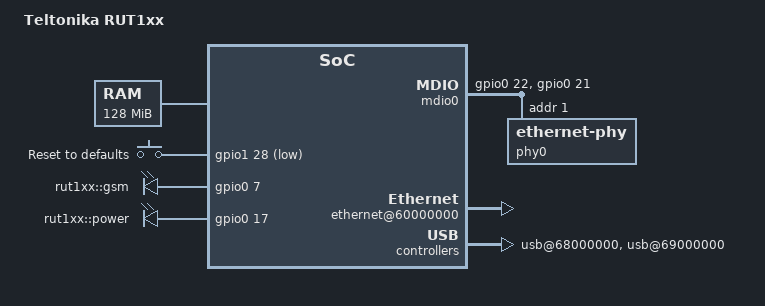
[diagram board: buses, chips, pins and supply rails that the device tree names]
/dts-v1/;
#include "gemini.dtsi"
#include <dt-bindings/input/input.h>
/ {
	model = "Teltonika RUT1xx";
	compatible = "teltonika,rut1xx", "cortina,gemini";
	#address-cells = <1>;
	#size-cells = <1>;
	memory@0 {  
		device_type = "memory";
		reg = <0x00000000 0x8000000>;
	};
	chosen {
		bootargs = "console=ttyS0,115200n8";
		stdout-path = &uart0;
	};
	gpio_keys {
		compatible = "gpio-keys";
		button-setup {
			debounce-interval = <100>;
			wakeup-source;
			linux,code = <KEY_SETUP>;
			label = "Reset to defaults";
			gpios = <&gpio1 28 GPIO_ACTIVE_LOW>;
		};
	};
	leds {
		compatible = "gpio-leds";
		led-gsm {
			label = "rut1xx::gsm";
			gpios = <&gpio0 7 GPIO_ACTIVE_HIGH>;
			default-state = "on";
		};
		led-power {
			label = "rut1xx::power";
			gpios = <&gpio0 17 GPIO_ACTIVE_HIGH>;
			default-state = "off";
			linux,default-trigger = "heartbeat";
		};
	};
	mdio0: mdio {
		compatible = "virtual,mdio-gpio";
		gpios = <&gpio0 22 GPIO_ACTIVE_HIGH>,  
			<&gpio0 21 GPIO_ACTIVE_HIGH>;  
		#address-cells = <1>;
		#size-cells = <0>;
		phy0: ethernet-phy@1 {
			reg = <1>;
			device_type = "ethernet-phy";
		};
	};
	soc {
		flash@30000000 {
			status = "okay";
			reg = <0x30000000 0x00800000>;
		};
		syscon: syscon@40000000 {
			pinctrl {
				gpio0_default_pins: pinctrl-gpio0 {
					mux {
						function = "gpio0";
						groups = "gpio0bgrp",
						"gpio0fgrp";
					};
				};
				gpio1_default_pins: pinctrl-gpio1 {
					mux {
						function = "gpio1";
						groups = "gpio1dgrp";
					};
				};
			};
		};
		gpio0: gpio@4d000000 {
			pinctrl-names = "default";
			pinctrl-0 = <&gpio0_default_pins>;
		};
		gpio1: gpio@4e000000 {
			pinctrl-names = "default";
			pinctrl-0 = <&gpio1_default_pins>;
		};
		ethernet@60000000 {
			status = "okay";
			ethernet-port@0 {
				phy-mode = "rgmii";
				phy-handle = <&phy0>;
			};
			ethernet-port@1 {
			};
		};
		usb@68000000 {
			status = "okay";
		};
		usb@69000000 {
			status = "okay";
		};
	};
};
